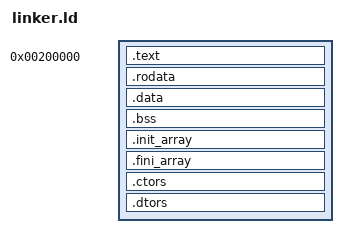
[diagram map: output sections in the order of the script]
/* The bootloader will look at this image and start execution at the symbol
   designated as the entry point. */
ENTRY(_start)

/* Tell where the various sections of the object files will be put in the final
   kernel image. */
SECTIONS
{
    /* Begin putting sections at 2 MiB, a safe place for kernels to be loaded */
    . = 2M;

    /* First put the multiboot2 header, as it is required to be put in the first
       32768 bytes in the image or the bootloader won't recognize the format.
       Next we'll put the .text section. */
    .text BLOCK(4K) : ALIGN(4K)
    {
        *(.multiboot2)
        *(.text)
    }

    /* Read-only data. */
    .rodata BLOCK(4K) : ALIGN(4K)
    {
        *(.rodata)
    }

    /* Read-write data (initialized) */
    .data BLOCK(4K) : ALIGN(4K)
    {
        *(.data)
    }

    /* Read-write data (uninitialized) and stack */
    .bss BLOCK(4K) : ALIGN(4K)
    {
        *(COMMON)
        *(.bss)
    }

    /* Modern global constructors */
    .init_array :
    {
        PROVIDE_HIDDEN (__init_array_start = .);
        KEEP (*(SORT_BY_INIT_PRIORITY(.init_array.*) SORT_BY_INIT_PRIORITY(.ctors.*)))
        KEEP (*(.init_array EXCLUDE_FILE (*crtbegin.o *crtbegin?.o *crtend.o *crtend?.o ) .ctors))
        PROVIDE_HIDDEN (__init_array_end = .);
    }

    /* Modern global destructors */
    .fini_array :
    {
        PROVIDE_HIDDEN (__fini_array_start = .);
        KEEP (*(SORT_BY_INIT_PRIORITY(.fini_array.*) SORT_BY_INIT_PRIORITY(.dtors.*)))
        KEEP (*(.fini_array EXCLUDE_FILE (*crtbegin.o *crtbegin?.o *crtend.o *crtend?.o ) .dtors))
        PROVIDE_HIDDEN (__fini_array_end = .);
    }

    /* Compiler process initialization */
    .ctors :
    {
        KEEP (*crtbegin.o(.ctors))
        KEEP (*crtbegin?.o(.ctors))
        KEEP (*(EXCLUDE_FILE (*crtend.o *crtend?.o ) .ctors))
        KEEP (*(SORT(.ctors.*)))
        KEEP (*(.ctors))
    }

    /* Compiler process finalization */
    .dtors :
    {
        KEEP (*crtbegin.o(.dtors))
        KEEP (*crtbegin?.o(.dtors))
        KEEP (*(EXCLUDE_FILE (*crtend.o *crtend?.o ) .dtors))
        KEEP (*(SORT(.dtors.*)))
        KEEP (*(.dtors))
    }

    /* The compiler may produce other sections, put them in the proper place in
       in this file, if you'd like to include them in the final kernel. */
}
